VERSION ""

NS_ :

BS_:

BU_: VCU ELP_ElithionPack
VAL_TABLE_ ELP_BmsState_ENUMDEF 15 "PLUGGED_ON" 14 "PLUGGED_RESERVED" 13 "PLUGGED_DISCHRG2HOME" 12 "PLUGGED_DISCHRG2GRID" 11 "PLUGGED_PREPTODISCHRG" 10 "PLUGGED_CHRGGRID" 9 "PLUGGED_PREPTOCHRG" 8 "PLUGGED_IDLE" 7 "UNPLUGGED_RESERVED" 6 "UNPLUGGED_RESERVED" 5 "UNPLUGGED_RESERVED" 4 "UNPLUGGED_OFF_CHRGDEPLETE" 3 "UNPLUGGED_OFF_CHRGSUSTAINED" 2 "UNPLUGGED_OFF_RELAYOFF" 1 "UNPLUGGED_OFF_CHRGOFFGRID" 0 "UNPLUGGED_OFF" ;

BO_ 1586 ELP_ContactorRequest: 8 VCU
 SG_ ELP_ContactorRequest : 7|8@0+ (1,0) [0|0] ""  ELP_ElithionPack

BO_ 1569 ELP_Revision: 8 ELP_ElithionPack
 SG_ ELP_ElithionRevision : 7|64@0- (1,0) [0|0] "ASCII"  VCU

BO_ 1568 ELP_CompanyName: 8 ELP_ElithionPack
 SG_ ELP_ElithionName : 7|64@0- (1,0) [0|0] "ASCII"  VCU

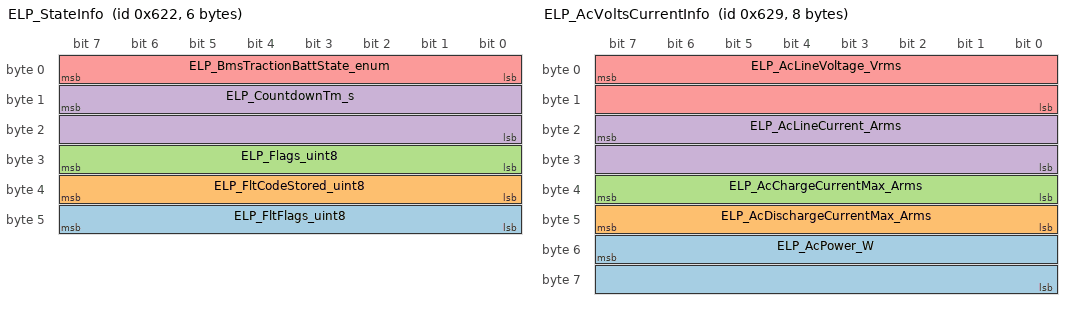
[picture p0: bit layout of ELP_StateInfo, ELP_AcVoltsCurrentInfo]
BO_ 1570 ELP_StateInfo: 6 ELP_ElithionPack
 SG_ ELP_FltFlags_uint8 : 47|8@0- (1,0) [0|0] ""  VCU
 SG_ ELP_FltCodeStored_uint8 : 39|8@0+ (1,0) [0|0] ""  VCU
 SG_ ELP_Flags_uint8 : 31|8@0+ (1,0) [0|0] ""  VCU
 SG_ ELP_CountdownTm_s : 15|16@0+ (1,0) [0|65535] ""  VCU
 SG_ ELP_BmsTractionBattState_enum : 7|8@0+ (1,0) [0|15] "enum"  VCU

BO_ 1578 ELP_ACEnergyInfo: 8 ELP_ElithionPack
 SG_ ELP_AcEnergyOut_Wh : 39|32@0+ (1,0) [0|4294967295] "Wh"  VCU
 SG_ ELP_AcEnergyIn_Wh : 7|32@0+ (1,0) [0|4294967295] "Wh"  VCU

BO_ 1577 ELP_AcVoltsCurrentInfo: 8 ELP_ElithionPack
 SG_ ELP_AcPower_W : 55|16@0- (1,0) [0|32700] "W"  VCU
 SG_ ELP_AcDischargeCurrentMax_Arms : 47|8@0+ (1,0) [0|255] "Arms"  VCU
 SG_ ELP_AcChargeCurrentMax_Arms : 39|8@0+ (1,0) [0|255] "Arms"  VCU
 SG_ ELP_AcLineCurrent_Arms : 23|16@0- (0.00390625,0) [0|127] "Arms"  VCU
 SG_ ELP_AcLineVoltage_Vrms : 7|16@0+ (1,0) [0|65500] "Vrms"  VCU

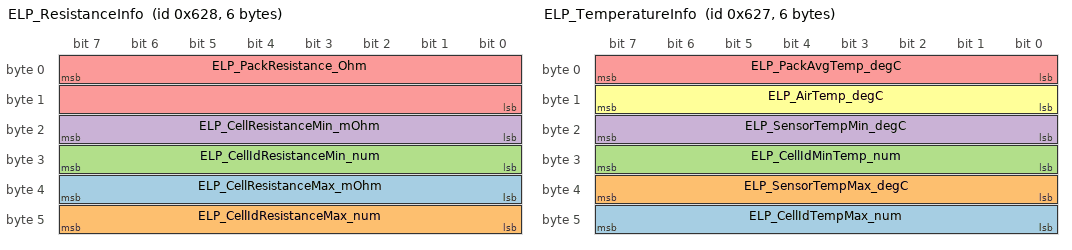
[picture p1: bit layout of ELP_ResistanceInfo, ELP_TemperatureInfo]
BO_ 1576 ELP_ResistanceInfo: 6 ELP_ElithionPack
 SG_ ELP_CellResistanceMax_mOhm : 39|8@0+ (0.1,0) [0|25.5] "mOhm"  VCU
 SG_ ELP_CellIdResistanceMax_num : 47|8@0+ (1,0) [0|254] "num"  VCU
 SG_ ELP_CellIdResistanceMin_num : 31|8@0+ (1,0) [0|254] "num"  VCU
 SG_ ELP_CellResistanceMin_mOhm : 23|8@0+ (0.1,0) [0|25.5] "mOhm"  VCU
 SG_ ELP_PackResistance_Ohm : 7|16@0+ (0.001,0) [0|65] "Ohm"  VCU

BO_ 1575 ELP_TemperatureInfo: 6 ELP_ElithionPack
 SG_ ELP_CellIdTempMax_num : 47|8@0- (1,0) [0|254] "num"  VCU
 SG_ ELP_SensorTempMax_degC : 39|8@0- (1,0) [-128|127] "degC"  VCU
 SG_ ELP_CellIdMinTemp_num : 31|8@0+ (1,0) [0|254] "num"  VCU
 SG_ ELP_SensorTempMin_degC : 23|8@0- (1,0) [-128|127] "degC"  VCU
 SG_ ELP_PackAvgTemp_degC : 7|8@0- (1,0) [-128|127] "degC"  VCU
 SG_ ELP_AirTemp_degC : 15|8@0- (1,0) [-128|127] "degC"  VCU

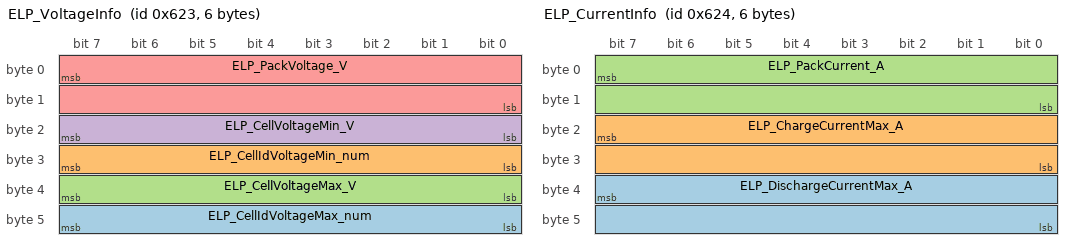
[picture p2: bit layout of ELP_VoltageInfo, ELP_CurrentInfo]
BO_ 1571 ELP_VoltageInfo: 6 ELP_ElithionPack
 SG_ ELP_CellIdVoltageMax_num : 47|8@0+ (1,0) [0|254] "num"  VCU
 SG_ ELP_CellIdVoltageMin_num : 31|8@0- (1,0) [0|254] "num"  VCU
 SG_ ELP_CellVoltageMax_V : 39|8@0+ (0.1,0) [0|25.5] "V"  VCU
 SG_ ELP_CellVoltageMin_V : 23|8@0+ (0.1,0) [0|25.5] "V"  VCU
 SG_ ELP_PackVoltage_V : 7|16@0+ (1,0) [0|65000] "V"  VCU

BO_ 1574 ELP_SOCInfo: 7 ELP_ElithionPack
 SG_ ELP_SOH_pc : 55|8@0- (1,0) [0|100] "pc"  VCU
 SG_ ELP_SOC2_pc : 47|8@0- (1,0) [0|100] "pc"  VCU
 SG_ ELP_Capacity_Ah : 31|16@0+ (1,0) [0|65000] "Ah"  VCU
 SG_ ELP_DOD_Ah : 15|16@0+ (1,0) [0|65000] "Ah"  VCU
 SG_ ELP_SOC_pc : 0|8@0+ (1,0) [0|100] "pc"  VCU

BO_ 1573 ELP_BattEnergyInfo: 8 ELP_ElithionPack
 SG_ ELP_BattEnergyOut_Wh : 39|32@0+ (1,0) [0|32000] "Wh"  VCU
 SG_ ELP_BatteryEnergyIn_Wh : 7|32@0+ (1,0) [0|32000] "Wh"  VCU

BO_ 1572 ELP_CurrentInfo: 6 ELP_ElithionPack
 SG_ ELP_DischargeCurrentMax_A : 39|16@0+ (1,0) [0|32000] "A"  VCU
 SG_ ELP_ChargeCurrentMax_A : 23|16@0- (1,0) [0|32000] "A"  VCU
 SG_ ELP_PackCurrent_A : 7|16@0- (1,0) [-32000|32000] "A"  VCU

CM_ SG_ 1569 ELP_ElithionRevision "Rev level: F1.04 = Harware rev F, Software rev 1.04";
CM_ SG_ 1568 ELP_ElithionName "ASCII, starting from rev 0.97";
CM_ SG_ 1570 ELP_FltFlags_uint8 "Fault bit flags. Fault type on each bit (see eLithion documentation) ";
CM_ SG_ 1570 ELP_FltCodeStored_uint8 "Fault code, stored (see eLithion documenation0";
CM_ SG_ 1570 ELP_Flags_uint8 "Bit flags of operation (see eLithion documentation)";
CM_ SG_ 1570 ELP_CountdownTm_s "Countdown time (s) to next state change";
CM_ SG_ 1570 ELP_BmsTractionBattState_enum "State of Traction battery system
";
CM_ SG_ 1578 ELP_AcEnergyOut_Wh "AC charger power out  [Wh] since manufacture";
CM_ SG_ 1578 ELP_AcEnergyIn_Wh "AC charger power in [Wh] since manufacture";
CM_ SG_ 1577 ELP_AcPower_W "AC line real power [W]";
CM_ SG_ 1577 ELP_AcDischargeCurrentMax_Arms "AC discharge current maximum available (A)";
CM_ SG_ 1577 ELP_AcChargeCurrentMax_Arms "AC charge current mximum acceptable (A)";
CM_ SG_ 1577 ELP_AcLineCurrent_Arms "AC Line current (Arms)";
CM_ SG_ 1577 ELP_AcLineVoltage_Vrms "AC line voltage [Vrms]";
CM_ SG_ 1576 ELP_CellResistanceMax_mOhm "Resistances [100 microohm] of highest resistance cells (or block of cells)";
CM_ SG_ 1576 ELP_CellIdResistanceMax_num "ID of the cell (or block of cells) that has the highest resistance";
CM_ SG_ 1576 ELP_CellIdResistanceMin_num "ID of the cell (or block of cells) that has the lowest resistance";
CM_ SG_ 1576 ELP_CellResistanceMin_mOhm "Resistances [100 microohm] of lowest cells (or block of cells)";
CM_ SG_ 1576 ELP_PackResistance_Ohm "Resistance of pack [ohm]";
CM_ SG_ 1575 ELP_CellIdTempMax_num "ID of the cell (or block of cells) that has the highest temperature";
CM_ SG_ 1575 ELP_SensorTempMax_degC "Temperatures [°C] of hottest sensors";
CM_ SG_ 1575 ELP_CellIdMinTemp_num "ID of the cell (or block of cells) that has the lowest temperature";
CM_ SG_ 1575 ELP_SensorTempMin_degC "Temperatures [°C] of coldest sensors";
CM_ SG_ 1575 ELP_PackAvgTemp_degC " Average pack temperature,e [°C]";
CM_ SG_ 1575 ELP_AirTemp_degC " Air intake temperature [°C]";
CM_ SG_ 1571 ELP_CellIdVoltageMax_num "ID of the cell (or block of cells) that has the highest voltage";
CM_ SG_ 1571 ELP_CellIdVoltageMin_num "ID of the cell (or block of cells) that has the lowest voltage";
CM_ SG_ 1571 ELP_CellVoltageMax_V "Voltages [V] of  most charged cells or blocks of cells,";
CM_ SG_ 1571 ELP_CellVoltageMin_V "Voltages [V] of least charged  cells or blocks of cells";
CM_ SG_ 1571 ELP_PackVoltage_V "Total voltage of pack [V]";
CM_ SG_ 1574 ELP_SOH_pc "State Of Charge of 2nd pack (such as the vehicle's original pack) [%], 
 When deeply discharged, its value does not go below 0";
CM_ SG_ 1574 ELP_SOC2_pc "State Of Charge of 2nd pack (such as the vehicle's original pack) [%],
When deeply discharged, its value does not go below 0";
CM_ SG_ 1574 ELP_Capacity_Ah "Actual capacity of the pack, (Ah)";
CM_ SG_ 1574 ELP_DOD_Ah "Depth of discharge, when deeply discharged its value may exceed capacity (Ah)";
CM_ SG_ 1574 ELP_SOC_pc "State of Charge";
CM_ SG_ 1573 ELP_BattEnergyOut_Wh "Total energy out of the battery (Wh)";
CM_ SG_ 1573 ELP_BatteryEnergyIn_Wh "Total energy into the battery (Wh)";
CM_ SG_ 1572 ELP_DischargeCurrentMax_A "Maximum current available for discharging";
CM_ SG_ 1572 ELP_ChargeCurrentMax_A "Maximum current acceptable for charging";
CM_ SG_ 1572 ELP_PackCurrent_A "Peak current +Ve is out of pack";
BA_DEF_ SG_  "GenSigSendType" ENUM  "Cyclic","OnWrite","OnWriteWithRepetition","OnChange","OnChangeWithRepetition","IfActive","IfActiveWithRepetition","NoSigSendType";
BA_DEF_ BO_  "GenMsgCycleTime" INT 0 0;
BA_DEF_ BO_  "GenMsgSendType" ENUM  "Cyclic","not_used","not_used","not_used","not_used","Cyclic","not_used","IfActive","NoMsgSendType";
BA_DEF_ BU_  "NmStationAddress" HEX 0 0;
BA_DEF_  "DBName" STRING ;
BA_DEF_  "BusType" STRING ;
BA_DEF_DEF_  "GenSigSendType" "Cyclic";
BA_DEF_DEF_  "GenMsgCycleTime" 0;
BA_DEF_DEF_  "GenMsgSendType" "NoMsgSendType";
BA_DEF_DEF_  "NmStationAddress" 0;
BA_DEF_DEF_  "DBName" "";
BA_DEF_DEF_  "BusType" "CAN";
BA_ "DBName" "CAN_PTC_J1";
BA_ "NmStationAddress" BU_ VCU 1280;
BA_ "NmStationAddress" BU_ ELP_ElithionPack 1568;
BA_ "GenMsgCycleTime" BO_ 1569 1;
BA_ "GenMsgCycleTime" BO_ 1568 1;
BA_ "GenMsgCycleTime" BO_ 1570 1;
BA_ "GenMsgCycleTime" BO_ 1578 1;
BA_ "GenMsgCycleTime" BO_ 1577 1;
BA_ "GenMsgCycleTime" BO_ 1576 1;
BA_ "GenMsgCycleTime" BO_ 1575 1;
BA_ "GenMsgCycleTime" BO_ 1571 1;
BA_ "GenMsgCycleTime" BO_ 1574 1;
BA_ "GenMsgCycleTime" BO_ 1573 1;
BA_ "GenMsgCycleTime" BO_ 1572 1;
VAL_ 1570 ELP_BmsTractionBattState_enum 15 "PLUGGED_ON" 14 "PLUGGED_RESERVED" 13 "PLUGGED_DISCHRG2HOME" 12 "PLUGGED_DISCHRG2GRID" 11 "PLUGGED_PREPTODISCHRG" 10 "PLUGGED_CHRGGRID" 9 "PLUGGED_PREPTOCHRG" 8 "PLUGGED_IDLE" 7 "UNPLUGGED_RESERVED" 6 "UNPLUGGED_RESERVED" 5 "UNPLUGGED_RESERVED" 4 "UNPLUGGED_OFF_CHRGDEPLETE" 3 "UNPLUGGED_OFF_CHRGSUSTAINED" 2 "UNPLUGGED_OFF_RELAYOFF" 1 "UNPLUGGED_OFF_CHRGOFFGRID" 0 "UNPLUGGED_OFF" ;
